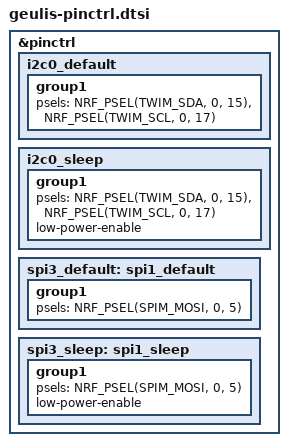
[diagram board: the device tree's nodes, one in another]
/*
* Copyright (c) 2022 The ZMK Contributors
* SPDX-License-Identifier: MIT
*/

&pinctrl {
	i2c0_default: i2c0_default {
		group1 {
			psels = <NRF_PSEL(TWIM_SDA, 0, 15)>,
			<NRF_PSEL(TWIM_SCL, 0, 17)>;
		};
	};
	
	i2c0_sleep: i2c0_sleep {
		group1 {
			psels = <NRF_PSEL(TWIM_SDA, 0, 15)>,
			<NRF_PSEL(TWIM_SCL, 0, 17)>;
			low-power-enable;
		};
	};
	
	spi3_default: spi1_default {
		group1 {
			psels = <NRF_PSEL(SPIM_MOSI, 0, 5)>;
			
		};
	};
	
	spi3_sleep: spi1_sleep {
		group1 {
			psels = <NRF_PSEL(SPIM_MOSI, 0, 5)>;
			low-power-enable;
		};
	};
};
